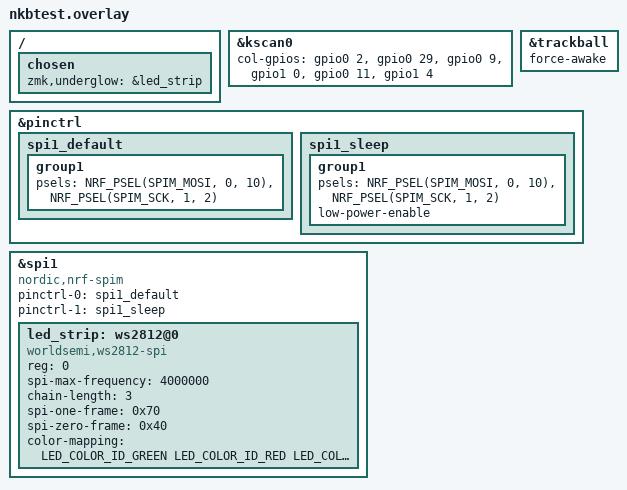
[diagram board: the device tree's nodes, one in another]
/* Standalone bench test: trackball + 3 keys (R1xC1/C2/C3) + RGB (SK6812). */
#include "nice_kb.dtsi"
#include <zephyr/dt-bindings/led/led.h>

&kscan0 {
    col-gpios
        = <&gpio0  2 (GPIO_ACTIVE_HIGH | GPIO_PULL_DOWN)>   /* col1 P0.02 */
        , <&gpio0 29 (GPIO_ACTIVE_HIGH | GPIO_PULL_DOWN)>   /* col2 P0.29 */
        , <&gpio0  9 (GPIO_ACTIVE_HIGH | GPIO_PULL_DOWN)>   /* col3 P0.09 (NFC) */
        , <&gpio1  0 (GPIO_ACTIVE_HIGH | GPIO_PULL_DOWN)>   /* col4 P1.00 */
        , <&gpio0 11 (GPIO_ACTIVE_HIGH | GPIO_PULL_DOWN)>   /* col5 P0.11 */
        , <&gpio1  4 (GPIO_ACTIVE_HIGH | GPIO_PULL_DOWN)>   /* col6 P1.04 */
        ;
};

/* keep sensor in RUN mode */
&trackball {
    force-awake;
};

/* ---- RGB: SK6812 (GRB) on P0.10 via WS2812-over-SPI on spi1 ---- */
&pinctrl {
    spi1_default: spi1_default {
        group1 {
            /* MOSI = RGB data (P0.10). SCK is a DUMMY on an unused pin (P1.02):
               nRF SPIM needs SCK to clock out MOSI; WS2812 ignores the clock. */
            psels = <NRF_PSEL(SPIM_MOSI, 0, 10)>,
                <NRF_PSEL(SPIM_SCK, 1, 2)>;
        };
    };
    spi1_sleep: spi1_sleep {
        group1 {
            psels = <NRF_PSEL(SPIM_MOSI, 0, 10)>,
                <NRF_PSEL(SPIM_SCK, 1, 2)>;
            low-power-enable;
        };
    };
};

&spi1 {
    status = "okay";
    compatible = "nordic,nrf-spim";
    pinctrl-0 = <&spi1_default>;
    pinctrl-1 = <&spi1_sleep>;
    pinctrl-names = "default", "sleep";

    led_strip: ws2812@0 {
        compatible = "worldsemi,ws2812-spi";
        reg = <0>;
        spi-max-frequency = <4000000>;
        chain-length = <3>;               /* 3 keys -> 3 SK6812; adjust if different */
        spi-one-frame = <0x70>;
        spi-zero-frame = <0x40>;
        color-mapping = <LED_COLOR_ID_GREEN LED_COLOR_ID_RED LED_COLOR_ID_BLUE>;
    };
};

/ {
    chosen {
        zmk,underglow = &led_strip;
    };
};
